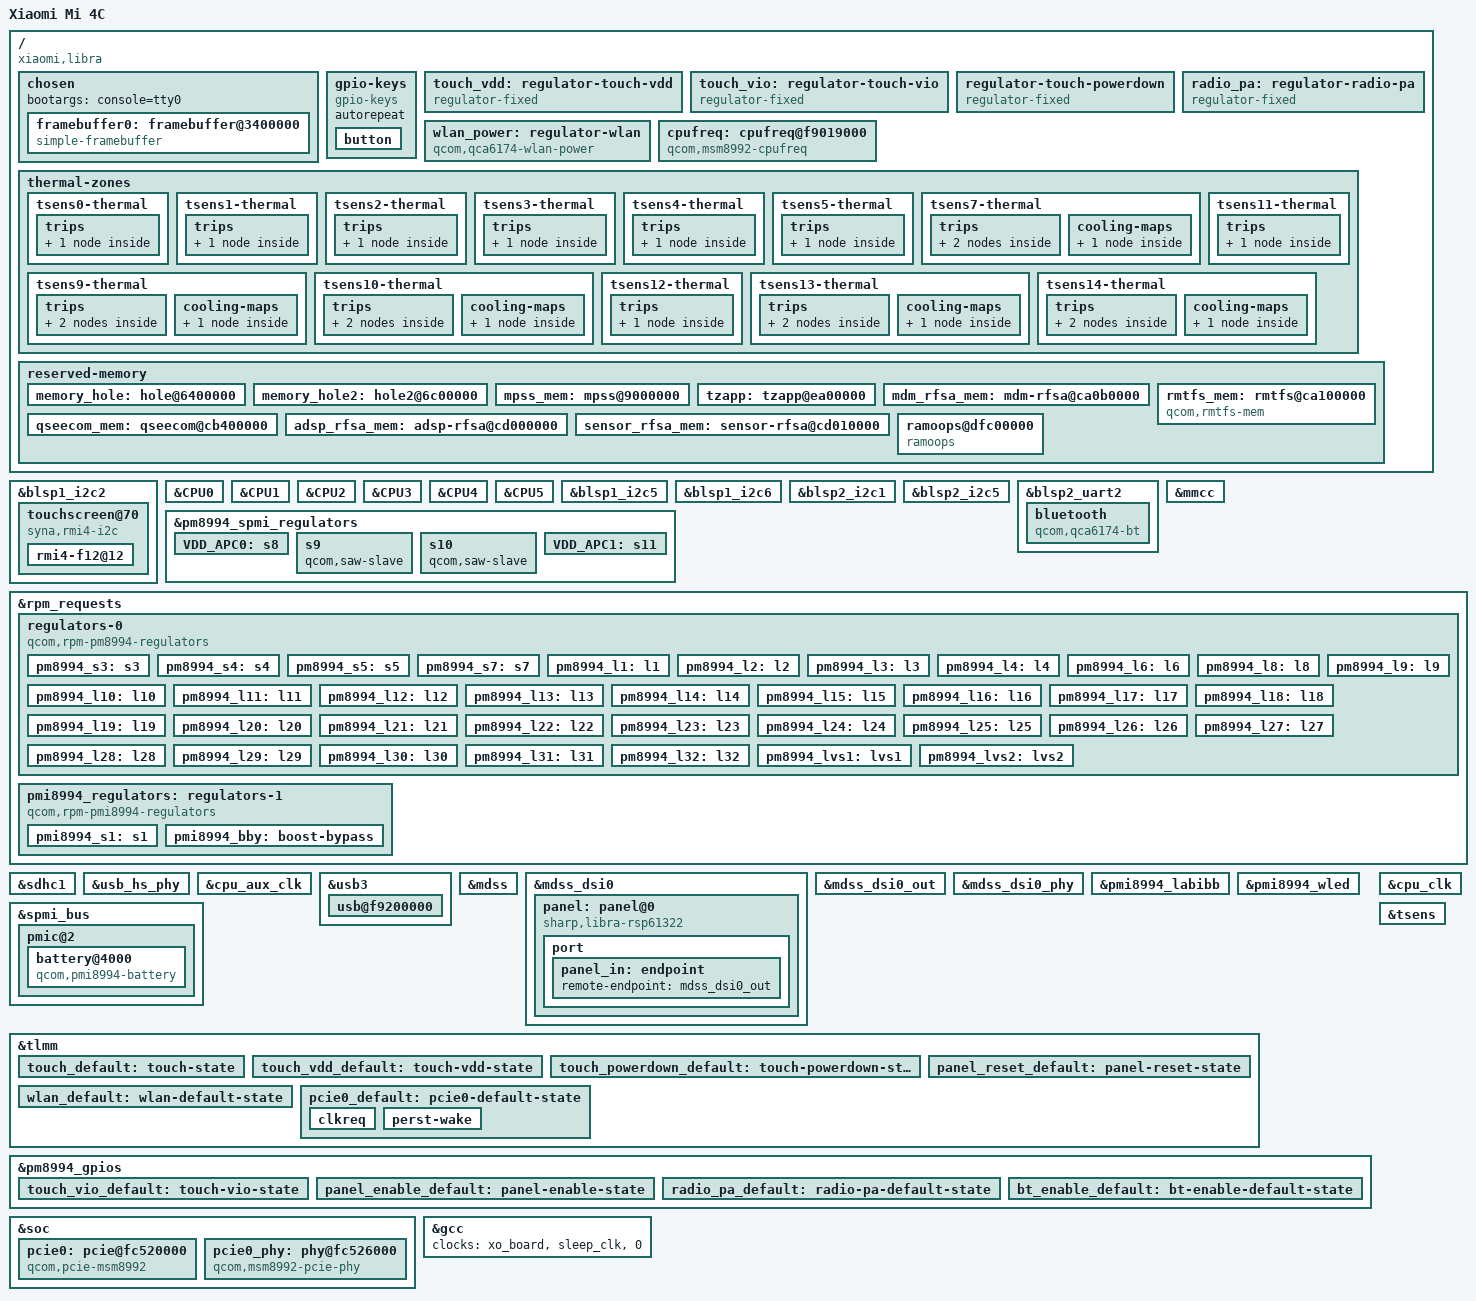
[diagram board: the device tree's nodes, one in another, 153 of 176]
// SPDX-License-Identifier: BSD-3-Clause
/*
 * Copyright (c) 2020, Konrad Dybcio
 */

/dts-v1/;

#include "msm8992.dtsi"
#include "pm8994.dtsi"
#include "pmi8994.dtsi"
#include <dt-bindings/gpio/gpio.h>
#include <dt-bindings/input/gpio-keys.h>
#include <dt-bindings/thermal/thermal.h>

/delete-node/ &adsp_mem;
/delete-node/ &audio_mem;
/delete-node/ &mpss_mem;
/delete-node/ &peripheral_region;
/delete-node/ &res_hyp_mem;
/delete-node/ &rmtfs_mem;

/ {
	model = "Xiaomi Mi 4C";
	compatible = "xiaomi,libra", "qcom,msm8992";
	chassis-type = "handset";

	/* required for bootloader to select correct board */
	qcom,msm-id = <251 0>, <252 0>;
	qcom,pmic-id = <65545 65546 0 0>;
	qcom,board-id = <12 0>;

	chosen {
		bootargs = "console=tty0";

		#address-cells = <2>;
		#size-cells = <2>;
		ranges;

		framebuffer0: framebuffer@3400000 {
			status = "okay";
			compatible = "simple-framebuffer";
			reg = <0 0x3400000 0 (1080 * 1920 * 3)>;
			width = <1080>;
			height = <1920>;
			stride = <(1080 * 3)>;
			format = "r8g8b8";
			/*
			 * Hold firmware display resources until native DRM handover.
			 */
			clocks = <&mmcc MDSS_AHB_CLK>,
				 <&mmcc MDSS_AXI_CLK>,
				 <&mmcc MDSS_VSYNC_CLK>,
				 <&mmcc MDSS_MDP_CLK>,
				 <&mmcc MDSS_BYTE0_CLK>,
				 <&mmcc MDSS_PCLK0_CLK>,
				 <&mmcc MDSS_ESC0_CLK>;
			power-domains = <&mmcc MDSS_GDSC>;
		};
	};

	gpio-keys {
		compatible = "gpio-keys";
		autorepeat;

		button {
			label = "Volume Up";
			gpios = <&pm8994_gpios 3 GPIO_ACTIVE_LOW>;
			linux,input-type = <1>;
			linux,code = <KEY_VOLUMEUP>;
			wakeup-source;
			debounce-interval = <15>;
		};
	};

	/* External touch rails and power-down control from factory x11 DTS. */
	touch_vdd: regulator-touch-vdd {
		compatible = "regulator-fixed";
		regulator-name = "ts_vreg";
		regulator-min-microvolt = <3100000>;
		regulator-max-microvolt = <3100000>;
		gpio = <&tlmm 110 GPIO_ACTIVE_HIGH>;
		enable-active-high;
		startup-delay-us = <10000>;
		pinctrl-names = "default";
		pinctrl-0 = <&touch_vdd_default>;
	};

	touch_vio: regulator-touch-vio {
		compatible = "regulator-fixed";
		regulator-name = "tp1v8_vreg";
		regulator-min-microvolt = <1800000>;
		regulator-max-microvolt = <1800000>;
		gpio = <&pm8994_gpios 2 GPIO_ACTIVE_HIGH>;
		enable-active-high;
		startup-delay-us = <10000>;
		pinctrl-names = "default";
		pinctrl-0 = <&touch_vio_default>;
	};

	regulator-touch-powerdown {
		compatible = "regulator-fixed";
		regulator-name = "tpwdn_vreg";
		regulator-min-microvolt = <3100000>;
		regulator-max-microvolt = <3100000>;
		gpio = <&tlmm 96 GPIO_ACTIVE_HIGH>;
		enable-active-high;
		startup-delay-us = <5000>;
		regulator-always-on;
		pinctrl-names = "default";
		pinctrl-0 = <&touch_powerdown_default>;
	};

	/* One shared OEM PA switch, refcounted by WLAN and Bluetooth. */
	radio_pa: regulator-radio-pa {
		compatible = "regulator-fixed";
		regulator-name = "qca6174-pa";
		gpio = <&pm8994_gpios 9 GPIO_ACTIVE_HIGH>;
		enable-active-high;
		startup-delay-us = <4000>;
		pinctrl-names = "default";
		pinctrl-0 = <&radio_pa_default>;
	};

	wlan_power: regulator-wlan {
		compatible = "qcom,qca6174-wlan-power";
		regulator-name = "qca6174-wlan";
		vddpa-supply = <&radio_pa>;
		vddio-supply = <&pm8994_s4>;
		vddxo-supply = <&pm8994_l30>;
		enable-gpios = <&tlmm 113 GPIO_ACTIVE_HIGH>;
		bootstrap-gpios = <&tlmm 112 GPIO_ACTIVE_HIGH>,
				  <&tlmm 54 GPIO_ACTIVE_HIGH>,
				  <&tlmm 53 GPIO_ACTIVE_HIGH>;
		pinctrl-names = "default";
		pinctrl-0 = <&wlan_default>;
	};

	cpufreq: cpufreq@f9019000 {
		compatible = "qcom,msm8992-cpufreq";
		reg = <0 0xf9019000 0 0x1000>, <0 0xf901a000 0 0x1000>;
		clocks = <&cpu_clk 0>, <&cpu_clk 1>, <&cpu_clk 2>;
		clock-names = "a53", "a57", "cci";
		apc0-supply = <&VDD_APC0>;
		apc1-supply = <&VDD_APC1>;
		qcom,saw-regs = <&apc0_saw>, <&apc1_saw>;
		power-domains = <&rpmpd MSM8994_VDDMX_AO>;
		nvmem-cells = <&cpr_row62>, <&cpr_row137>, <&cpr_row22>, <&cpr_row138>, <&cpr_row139>, <&cpr_row140>, <&cpr_row56>, <&cpr_row57>, <&cpr_row136>, <&cpu_speedbin>;
		nvmem-cell-names = "cpr-row62", "cpr-row137", "cpr-row22", "cpr-row138", "cpr-row139", "cpr-row140", "cpr-row56", "cpr-row57", "cpr-row136", "speedbin";
	};

	/* Factory polling, mitigation and emergency temperature limits. */
	thermal-zones {
		tsens0-thermal {
			polling-delay-passive = <250>;
			polling-delay = <250>;
			thermal-sensors = <&tsens 0>;
			trips {
				critical {
					temperature = <115000>;
					hysteresis = <0>;
					type = "critical";
				};
			};
		};
		tsens1-thermal {
			polling-delay-passive = <250>;
			polling-delay = <250>;
			thermal-sensors = <&tsens 1>;
			trips {
				critical {
					temperature = <115000>;
					hysteresis = <0>;
					type = "critical";
				};
			};
		};
		tsens2-thermal {
			polling-delay-passive = <250>;
			polling-delay = <250>;
			thermal-sensors = <&tsens 2>;
			trips {
				critical {
					temperature = <115000>;
					hysteresis = <0>;
					type = "critical";
				};
			};
		};
		tsens3-thermal {
			polling-delay-passive = <250>;
			polling-delay = <250>;
			thermal-sensors = <&tsens 3>;
			trips {
				critical {
					temperature = <115000>;
					hysteresis = <0>;
					type = "critical";
				};
			};
		};
		tsens4-thermal {
			polling-delay-passive = <250>;
			polling-delay = <250>;
			thermal-sensors = <&tsens 4>;
			trips {
				critical {
					temperature = <115000>;
					hysteresis = <0>;
					type = "critical";
				};
			};
		};
		tsens5-thermal {
			polling-delay-passive = <250>;
			polling-delay = <250>;
			thermal-sensors = <&tsens 5>;
			trips {
				critical {
					temperature = <115000>;
					hysteresis = <0>;
					type = "critical";
				};
			};
		};
		tsens7-thermal {
			polling-delay-passive = <250>;
			polling-delay = <250>;
			thermal-sensors = <&tsens 7>;
			trips {
				tsens7_passive: passive {
					temperature = <60000>;
					hysteresis = <10000>;
					type = "passive";
				};
				critical {
					temperature = <115000>;
					hysteresis = <0>;
					type = "critical";
				};
			};
			cooling-maps {
				map {
					trip = <&tsens7_passive>;
					cooling-device = <&CPU0 THERMAL_NO_LIMIT THERMAL_NO_LIMIT>, <&CPU4 THERMAL_NO_LIMIT THERMAL_NO_LIMIT>;
				};
			};
		};
		tsens9-thermal {
			polling-delay-passive = <250>;
			polling-delay = <250>;
			thermal-sensors = <&tsens 9>;
			trips {
				tsens9_passive: passive {
					temperature = <60000>;
					hysteresis = <10000>;
					type = "passive";
				};
				critical {
					temperature = <115000>;
					hysteresis = <0>;
					type = "critical";
				};
			};
			cooling-maps {
				map {
					trip = <&tsens9_passive>;
					cooling-device = <&CPU0 THERMAL_NO_LIMIT THERMAL_NO_LIMIT>;
				};
			};
		};
		tsens10-thermal {
			polling-delay-passive = <250>;
			polling-delay = <250>;
			thermal-sensors = <&tsens 10>;
			trips {
				tsens10_passive: passive {
					temperature = <60000>;
					hysteresis = <10000>;
					type = "passive";
				};
				critical {
					temperature = <115000>;
					hysteresis = <0>;
					type = "critical";
				};
			};
			cooling-maps {
				map {
					trip = <&tsens10_passive>;
					cooling-device = <&CPU0 THERMAL_NO_LIMIT THERMAL_NO_LIMIT>;
				};
			};
		};
		tsens11-thermal {
			polling-delay-passive = <250>;
			polling-delay = <250>;
			thermal-sensors = <&tsens 11>;
			trips {
				critical {
					temperature = <115000>;
					hysteresis = <0>;
					type = "critical";
				};
			};
		};
		tsens12-thermal {
			polling-delay-passive = <250>;
			polling-delay = <250>;
			thermal-sensors = <&tsens 12>;
			trips {
				critical {
					temperature = <115000>;
					hysteresis = <0>;
					type = "critical";
				};
			};
		};
		tsens13-thermal {
			polling-delay-passive = <250>;
			polling-delay = <250>;
			thermal-sensors = <&tsens 13>;
			trips {
				tsens13_passive: passive {
					temperature = <60000>;
					hysteresis = <10000>;
					type = "passive";
				};
				critical {
					temperature = <115000>;
					hysteresis = <0>;
					type = "critical";
				};
			};
			cooling-maps {
				map {
					trip = <&tsens13_passive>;
					cooling-device = <&CPU4 THERMAL_NO_LIMIT THERMAL_NO_LIMIT>;
				};
			};
		};
		tsens14-thermal {
			polling-delay-passive = <250>;
			polling-delay = <250>;
			thermal-sensors = <&tsens 14>;
			trips {
				tsens14_passive: passive {
					temperature = <60000>;
					hysteresis = <10000>;
					type = "passive";
				};
				critical {
					temperature = <115000>;
					hysteresis = <0>;
					type = "critical";
				};
			};
			cooling-maps {
				map {
					trip = <&tsens14_passive>;
					cooling-device = <&CPU4 THERMAL_NO_LIMIT THERMAL_NO_LIMIT>;
				};
			};
		};
	};

	reserved-memory {
		#address-cells = <2>;
		#size-cells = <2>;
		ranges;

		memory_hole: hole@6400000 {
			reg = <0 0x06400000 0 0x600000>;
			no-map;
		};

		memory_hole2: hole2@6c00000 {
			reg = <0 0x06c00000 0 0x2400000>;
			no-map;
		};

		mpss_mem: mpss@9000000 {
			reg = <0 0x09000000 0 0x5a00000>;
			no-map;
		};

		tzapp: tzapp@ea00000 {
			reg = <0 0x0ea00000 0 0x1900000>;
			no-map;
		};

		mdm_rfsa_mem: mdm-rfsa@ca0b0000 {
			reg = <0 0xca0b0000 0 0x10000>;
			no-map;
		};

		rmtfs_mem: rmtfs@ca100000 {
			compatible = "qcom,rmtfs-mem";
			reg = <0 0xca100000 0 0x180000>;
			no-map;

			qcom,client-id = <1>;
		};

		qseecom_mem: qseecom@cb400000 {
			reg = <0 0xcb400000 0 0x1c00000>;
			no-mem;
		};

		adsp_rfsa_mem: adsp-rfsa@cd000000 {
			reg = <0 0xcd000000 0 0x10000>;
			no-map;
		};

		sensor_rfsa_mem: sensor-rfsa@cd010000 {
			reg = <0 0xcd010000 0 0x10000>;
			no-map;
		};

		ramoops@dfc00000 {
			compatible = "ramoops";
			reg = <0 0xdfc00000 0 0x40000>;
			console-size = <0x10000>;
			record-size = <0x10000>;
			pmsg-size = <0x20000>;
		};
	};
};

&blsp1_i2c2 {
	status = "okay";

	/* TWRP confirms Biel/Sharp Synaptics DSX at 0x70 with F01/F12. */
	touchscreen@70 {
		compatible = "syna,rmi4-i2c";
		reg = <0x70>;
		interrupt-parent = <&tlmm>;
		interrupts = <61 IRQ_TYPE_LEVEL_LOW>;
		reset-gpios = <&tlmm 60 GPIO_ACTIVE_LOW>;
		vdd-supply = <&touch_vdd>;
		vio-supply = <&touch_vio>;
		pinctrl-names = "default";
		pinctrl-0 = <&touch_default>;
		syna,startup-delay-ms = <5>;
		syna,reset-delay-ms = <15>;
		#address-cells = <1>;
		#size-cells = <0>;

		rmi4-f12@12 {
			reg = <0x12>;
			syna,sensor-type = <1>;
		};
	};
};

&CPU0 {
	clocks = <&cpu_clk 0>;
	#cooling-cells = <2>;
	enable-method = "qcom,8994-arm-cortex-acc";
	qcom,acc = <&acc0>;
	qcom,l2-power = <&cpu_power>;
	qcom,ldo-retention-voltage = <0x2a>;
};

&CPU1 {
	clocks = <&cpu_clk 0>;
	#cooling-cells = <2>;
	enable-method = "qcom,8994-arm-cortex-acc";
	qcom,acc = <&acc1>;
	qcom,l2-power = <&cpu_power>;
	qcom,ldo-retention-voltage = <0x2a>;
};

&CPU2 {
	clocks = <&cpu_clk 0>;
	#cooling-cells = <2>;
	enable-method = "qcom,8994-arm-cortex-acc";
	qcom,acc = <&acc2>;
	qcom,l2-power = <&cpu_power>;
	qcom,ldo-retention-voltage = <0x2a>;
};

&CPU3 {
	clocks = <&cpu_clk 0>;
	#cooling-cells = <2>;
	enable-method = "qcom,8994-arm-cortex-acc";
	qcom,acc = <&acc3>;
	qcom,l2-power = <&cpu_power>;
	qcom,ldo-retention-voltage = <0x2a>;
};

&CPU4 {
	clocks = <&cpu_clk 1>;
	#cooling-cells = <2>;
	enable-method = "qcom,8994-arm-cortex-acc";
	qcom,acc = <&acc4>;
	qcom,l2-power = <&cpu_power>;
	qcom,ldo-retention-voltage = <0x3e>;
};

&CPU5 {
	clocks = <&cpu_clk 1>;
	#cooling-cells = <2>;
	enable-method = "qcom,8994-arm-cortex-acc";
	qcom,acc = <&acc5>;
	qcom,l2-power = <&cpu_power>;
	qcom,ldo-retention-voltage = <0x3e>;
};

&blsp1_i2c5 {
	status = "okay";

	/* ST lsm6db0 gyro/accelerometer */
};

&blsp1_i2c6 {
	status = "okay";

	/*
	 * NXP NCI NFC,
	 * TI USB320 Type-C controller,
	 * Pericom 30216a USB (de)mux switch
	 */
};

&blsp2_i2c1 {
	status = "okay";

	/* cm36686 proximity and ambient light sensor */
};

&blsp2_i2c5 {
	status = "okay";

	/* Silabs si4705 FM transmitter */
};

&blsp2_uart2 {
	status = "okay";

	bluetooth {
		compatible = "qcom,qca6174-bt";
		enable-gpios = <&pm8994_gpios 19 GPIO_ACTIVE_HIGH>;
		vddio-supply = <&pm8994_s4>;
		vddxo-supply = <&pm8994_l30>;
		vddrf-supply = <&radio_pa>;
		pinctrl-names = "default";
		pinctrl-0 = <&bt_enable_default>;
		max-speed = <3000000>;
		firmware-name = "btnv32.bin";
	};
};

&mmcc {
	/* Resolve DSI clocks by name when the MSM module registers its PLL.
	 * Direct PHY phandles would defer MMCC, which also supplies PHY AHB.
	 */
	clocks = <&xo_board>,
		 <&gcc GPLL0_OUT_MMSSCC>,
		 <&rpmcc RPM_SMD_MMSSNOC_AHB_CLK>,
		 <&rpmcc RPM_SMD_GFX3D_CLK_SRC>,
		 <0>, <0>, <0>, <0>, <0>;
};

&pm8994_spmi_regulators {
	VDD_APC0: s8 {
		qcom,saw-reg = <&apc0_saw>;
		qcom,saw-leader;
		qcom,saw-cpu = <&CPU0>;
		regulator-min-microvolt = <680000>;
		regulator-max-microvolt = <1180000>;
		regulator-always-on;
		regulator-boot-on;
	};

	/* APC1 is 3-phase, but quoting downstream, s11 is "the gang leader" */
	s9 {
		qcom,saw-slave;
	};

	s10 {
		qcom,saw-slave;
	};

	VDD_APC1: s11 {
		qcom,saw-reg = <&apc1_saw>;
		qcom,saw-leader;
		qcom,saw-cpu = <&CPU4>;
		regulator-min-microvolt = <700000>;
		regulator-max-microvolt = <1225000>;
		regulator-always-on;
		regulator-boot-on;
	};
};

&rpm_requests {
	regulators-0 {
		compatible = "qcom,rpm-pm8994-regulators";

		vdd_l1-supply = <&pm8994_s7>;
		vdd_l2_26_28-supply = <&pm8994_s3>;
		vdd_l3_11-supply = <&pm8994_s3>;
		vdd_l4_27_31-supply = <&pm8994_s3>;
		vdd_l5_7-supply = <&pm8994_s3>;
		vdd_l6_12_32-supply = <&pm8994_s5>;
		vdd_l8_16_30-supply = <&vph_pwr>;
		vdd_l9_10_18_22-supply = <&vph_pwr>;
		vdd_l13_19_23_24-supply = <&vph_pwr>;
		vdd_l14_15-supply = <&pm8994_s5>;
		vdd_l17_29-supply = <&vph_pwr>;
		vdd_l20_21-supply = <&vph_pwr>;
		vdd_l25-supply = <&pm8994_s5>;
		vdd_lvs1_2-supply = <&pm8994_s4>;

		/* S1, S2, S6 and S12 are managed by RPMPD */

		pm8994_s3: s3 {
			regulator-min-microvolt = <1300000>;
			regulator-max-microvolt = <1300000>;
		};

		pm8994_s4: s4 {
			regulator-min-microvolt = <1800000>;
			regulator-max-microvolt = <1800000>;
			regulator-allow-set-load;
			regulator-always-on;
			regulator-system-load = <325000>;
		};

		pm8994_s5: s5 {
			regulator-min-microvolt = <2150000>;
			regulator-max-microvolt = <2150000>;
		};

		pm8994_s7: s7 {
			regulator-min-microvolt = <1000000>;
			regulator-max-microvolt = <1000000>;
		};

		/* S8, S9, S10 and S11 - SPMI-managed VDD_APC */

		pm8994_l1: l1 {
			regulator-min-microvolt = <1000000>;
			regulator-max-microvolt = <1000000>;
		};

		pm8994_l2: l2 {
			regulator-min-microvolt = <1250000>;
			regulator-max-microvolt = <1250000>;
		};

		pm8994_l3: l3 {
			regulator-min-microvolt = <1200000>;
			regulator-max-microvolt = <1200000>;
		};

		pm8994_l4: l4 {
			regulator-min-microvolt = <1225000>;
			regulator-max-microvolt = <1225000>;
		};

		/* L5 is inaccessible from RPM */

		pm8994_l6: l6 {
			regulator-min-microvolt = <1800000>;
			regulator-max-microvolt = <1800000>;
		};

		/* L7 is inaccessible from RPM */

		pm8994_l8: l8 {
			regulator-min-microvolt = <1800000>;
			regulator-max-microvolt = <1800000>;
		};

		pm8994_l9: l9 {
			regulator-min-microvolt = <1800000>;
			regulator-max-microvolt = <1800000>;
		};

		pm8994_l10: l10 {
			regulator-min-microvolt = <1800000>;
			regulator-max-microvolt = <1800000>;
		};

		pm8994_l11: l11 {
			regulator-min-microvolt = <1200000>;
			regulator-max-microvolt = <1200000>;
		};

		pm8994_l12: l12 {
			regulator-min-microvolt = <1800000>;
			regulator-max-microvolt = <1800000>;
		};

		pm8994_l13: l13 {
			regulator-min-microvolt = <1800000>;
			regulator-max-microvolt = <2950000>;
		};

		pm8994_l14: l14 {
			regulator-min-microvolt = <1800000>;
			regulator-max-microvolt = <1800000>;
		};

		pm8994_l15: l15 {
			regulator-min-microvolt = <1800000>;
			regulator-max-microvolt = <1800000>;
		};

		pm8994_l16: l16 {
			regulator-min-microvolt = <2700000>;
			regulator-max-microvolt = <2700000>;
		};

		pm8994_l17: l17 {
			regulator-min-microvolt = <2700000>;
			regulator-max-microvolt = <2700000>;
		};

		pm8994_l18: l18 {
			regulator-min-microvolt = <2850000>;
			regulator-max-microvolt = <2850000>;
			regulator-always-on;
		};

		pm8994_l19: l19 {
			regulator-min-microvolt = <2800000>;
			regulator-max-microvolt = <2800000>;
		};

		pm8994_l20: l20 {
			regulator-min-microvolt = <2950000>;
			regulator-max-microvolt = <2950000>;
			regulator-always-on;
			regulator-boot-on;
			regulator-allow-set-load;
			regulator-system-load = <570000>;
		};

		pm8994_l21: l21 {
			regulator-min-microvolt = <2950000>;
			regulator-max-microvolt = <2950000>;
			regulator-always-on;
		};

		pm8994_l22: l22 {
			regulator-min-microvolt = <3000000>;
			regulator-max-microvolt = <3000000>;
		};

		pm8994_l23: l23 {
			regulator-min-microvolt = <2800000>;
			regulator-max-microvolt = <2800000>;
		};

		pm8994_l24: l24 {
			regulator-min-microvolt = <3075000>;
			regulator-max-microvolt = <3150000>;
		};

		pm8994_l25: l25 {
			regulator-min-microvolt = <1000000>;
			regulator-max-microvolt = <1000000>;
		};

		pm8994_l26: l26 {
			regulator-min-microvolt = <987500>;
			regulator-max-microvolt = <987500>;

		};

		pm8994_l27: l27 {
			regulator-min-microvolt = <1050000>;
			regulator-max-microvolt = <1050000>;
		};

		pm8994_l28: l28 {
			regulator-min-microvolt = <1000000>;
			regulator-max-microvolt = <1000000>;
		};

		pm8994_l29: l29 {
			regulator-min-microvolt = <2800000>;
			regulator-max-microvolt = <2800000>;
		};

		pm8994_l30: l30 {
			regulator-min-microvolt = <1800000>;
			regulator-max-microvolt = <1800000>;
		};

		pm8994_l31: l31 {
			regulator-min-microvolt = <1262500>;
			regulator-max-microvolt = <1262500>;
		};

		pm8994_l32: l32 {
			regulator-min-microvolt = <1800000>;
			regulator-max-microvolt = <1800000>;
		};

		pm8994_lvs1: lvs1 {};
		pm8994_lvs2: lvs2 {};
	};

	pmi8994_regulators: regulators-1 {
		compatible = "qcom,rpm-pmi8994-regulators";
		vdd_s1-supply = <&vph_pwr>;
		vdd_bst_byp-supply = <&vph_pwr>;

		pmi8994_s1: s1 {
			regulator-min-microvolt = <1025000>;
			regulator-max-microvolt = <1025000>;
		};

		/* S2 & S3 - VDD_GFX */

		pmi8994_bby: boost-bypass {
			regulator-min-microvolt = <3150000>;
			regulator-max-microvolt = <3600000>;
		};
	};
};

&sdhc1 {
	status = "okay";

	mmc-hs400-1_8v;
	vmmc-supply = <&pm8994_l20>;
	vqmmc-supply = <&pm8994_s4>;
};

&usb_hs_phy {
	vdda1p8-supply = <&pm8994_l6>;
	vdda3p3-supply = <&pm8994_l24>;
	status = "okay";
};

&cpu_aux_clk {
	status = "okay";
};

&usb3 {
	usb@f9200000 {
		phys = <&usb_hs_phy>;
		phy-names = "usb2-phy";
		snps,hsphy_interface = "utmi";
	};
};

&mdss {
	status = "okay";
};

&mdss_dsi0 {
	status = "okay";
	vdda-supply = <&pm8994_l2>;
	vddio-supply = <&pm8994_l12>;
	vcca-supply = <&pm8994_l28>;
	vdd-supply = <&pm8994_l14>;

	panel: panel@0 {
		compatible = "sharp,libra-rsp61322";
		reg = <0>;
		avdd-supply = <&pmi8994_lab>;
		avee-supply = <&pmi8994_ibb>;
		reset-gpios = <&tlmm 78 GPIO_ACTIVE_LOW>;
		enable-gpios = <&pm8994_gpios 14 GPIO_ACTIVE_HIGH>;
		backlight = <&pmi8994_wled>;
		pinctrl-names = "default";
		pinctrl-0 = <&panel_reset_default &panel_enable_default>;
		port {
			panel_in: endpoint {
				remote-endpoint = <&mdss_dsi0_out>;
			};
		};
	};
};

&mdss_dsi0_out {
	remote-endpoint = <&panel_in>;
	data-lanes = <0 1 2 3>;
};

&mdss_dsi0_phy {
	status = "okay";
	vddio-supply = <&pm8994_l12>;
	vcca-supply = <&pm8994_l28>;
};

&pmi8994_labibb {
	status = "okay";
};

&pmi8994_wled {
	status = "okay";
	/* Linux controls brightness directly without a panel CABC PWM signal. */
	/delete-property/ qcom,cabc;
	/* Illuminate only after native fbcon scanout has been checked. */
	default-brightness = <0>;
	qcom,fdbk-output = "auto";
	qcom,vref-mv = <350>;
	/* The selected factory DT overrides the vendor's generic 104 ns default. */
	qcom,boost-duty-ns = <26>;
	qcom,mod-freq-khz = <9600>;
	qcom,dim-mode = "hybrid";
	qcom,hyb-thres = <625>;
	qcom,sync-dly-us = <800>;
	qcom,en-phase-stag;
	qcom,current-limit-microamp = <20000>;
	/* Vendor ILIM encoding: 980 / 280 = 3; WLED4 table entry 3 is 620. */
	qcom,current-boost-limit = <620>;
	qcom,switching-freq = <600>;
	qcom,ovp-millivolt = <29500>;
	qcom,enabled-strings = <0 1>;
};

&spmi_bus {
	pmic@2 {
		battery@4000 {
			compatible = "qcom,pmi8994-battery";
			reg = <0x4000>;
			/* OEM x11 fastchg-current-ma=1800, float-voltage-mv=4400. */
			qcom,fast-charge-current-max-microamp = <1800000>;
			qcom,battery-voltage-max-microvolt = <4400000>;
			interrupts = <2 0x40 4 IRQ_TYPE_EDGE_BOTH>,
				     <2 0x40 1 IRQ_TYPE_EDGE_BOTH>,
				     <2 0x41 6 IRQ_TYPE_EDGE_BOTH>,
				     <2 0x13 2 IRQ_TYPE_EDGE_BOTH>,
				     <2 0x12 0 IRQ_TYPE_EDGE_BOTH>,
				     <2 0x12 2 IRQ_TYPE_EDGE_BOTH>;
			interrupt-names = "delta-soc", "low-soc", "batt-missing",
					  "usb-source", "batt-hot", "batt-cold";
		};
	};
};

&tlmm {
	touch_default: touch-state {
		pins = "gpio60", "gpio61";
		function = "gpio";
		drive-strength = <16>;
		bias-pull-up;
	};

	touch_vdd_default: touch-vdd-state {
		pins = "gpio110";
		function = "gpio";
		drive-strength = <16>;
		bias-pull-up;
	};

	touch_powerdown_default: touch-powerdown-state {
		pins = "gpio96";
		function = "gpio";
		drive-strength = <16>;
		bias-pull-up;
	};

	panel_reset_default: panel-reset-state {
		pins = "gpio78";
		function = "gpio";
		drive-strength = <8>;
		bias-disable;
	};
};

&pm8994_gpios {
	touch_vio_default: touch-vio-state {
		pins = "gpio2";
		function = "normal";
		power-source = <2>;
		bias-disable;
	};

	panel_enable_default: panel-enable-state {
		pins = "gpio14";
		function = "normal";
		power-source = <2>;
		bias-disable;
	};
};

&cpu_clk {
	status = "okay";
};

&tsens {
	status = "okay";
};

/* OEM PCIe0 aperture and 20nm PHY, separate from the working USB PHY. */
&soc {
	pcie0: pcie@fc520000 {
		compatible = "qcom,pcie-msm8992";
		device_type = "pci";
		reg = <0xfc520000 0x2000>, <0xff000000 0xf1d>,
		      <0xff000f20 0xa8>, <0xff100000 0x100000>;
		reg-names = "parf", "dbi", "elbi", "config";
		#address-cells = <3>;
		#size-cells = <2>;
		#interrupt-cells = <1>;
		bus-range = <0 0xff>;
		linux,pci-domain = <0>;
		num-lanes = <1>;
		ranges = <0x01000000 0 0xff200000 0xff200000 0 0x100000>,
			 <0x02000000 0 0xff300000 0xff300000 0 0xd00000>;
		interrupts = <GIC_SPI 243 IRQ_TYPE_LEVEL_HIGH>;
		interrupt-names = "msi";
		interrupt-map-mask = <0 0 0 7>;
		interrupt-map = <0 0 0 1 &intc 0 244 IRQ_TYPE_LEVEL_HIGH>,
				<0 0 0 2 &intc 0 245 IRQ_TYPE_LEVEL_HIGH>,
				<0 0 0 3 &intc 0 247 IRQ_TYPE_LEVEL_HIGH>,
				<0 0 0 4 &intc 0 248 IRQ_TYPE_LEVEL_HIGH>;
		clocks = <&rpmcc RPM_SMD_LN_BB_CLK>,
			 <&gcc GCC_PCIE_0_AUX_CLK>,
			 <&gcc GCC_PCIE_0_CFG_AHB_CLK>,
			 <&gcc GCC_PCIE_0_MSTR_AXI_CLK>,
			 <&gcc GCC_PCIE_0_SLV_AXI_CLK>,
			 <&gcc PCIE_0_PHY_LDO>;
		clock-names = "ref", "aux", "cfg", "bus_master", "bus_slave", "ldo";
		power-domains = <&gcc PCIE_0_GDSC>;
		resets = <&gcc PCIE_PHY_0_RESET>;
		reset-names = "phy";

		vdda-supply = <&pm8994_l12>;
		vdda_phy-supply = <&pm8994_l28>;
		vddpe-3v3-supply = <&wlan_power>;
		perst-gpios = <&tlmm 35 GPIO_ACTIVE_LOW>;
		wake-gpios = <&tlmm 37 GPIO_ACTIVE_LOW>;
		pinctrl-names = "default";
		pinctrl-0 = <&pcie0_default>;
		phys = <&pcie0_phy>;
		phy-names = "pciephy";
	};

	pcie0_phy: phy@fc526000 {
		compatible = "qcom,msm8992-pcie-phy";
		reg = <0xfc526000 0x1000>;
		clocks = <&gcc GCC_PCIE_0_PIPE_CLK>;
		clock-names = "pipe";
		resets = <&gcc PCIE_PHY_0_PIPE_RESET>;
		reset-names = "pipe";
		#phy-cells = <0>;
		#clock-cells = <0>;
	};
};

&gcc {
	/* Resolve the PHY's PIPE output by name to avoid a GCC/PHY probe cycle. */
	clocks = <&xo_board>, <&sleep_clk>, <0>;
	clock-names = "xo", "sleep", "pcie0_pipe";
};

&tlmm {
	wlan_default: wlan-default-state {
		pins = "gpio112", "gpio54", "gpio53", "gpio113";
		function = "gpio";
		drive-strength = <16>;
		bias-pull-down;
	};

	pcie0_default: pcie0-default-state {
		clkreq {
			pins = "gpio36";
			/* GPIO36 function 2, named pci_e1 in the MSM8994 mux table. */
			function = "pci_e1";
			drive-strength = <2>;
			bias-pull-up;
		};
		perst-wake {
			pins = "gpio35", "gpio37";
			function = "gpio";
			drive-strength = <2>;
			bias-pull-down;
		};
	};
};

&pm8994_gpios {
	radio_pa_default: radio-pa-default-state {
		pins = "gpio9";
		function = "normal";
		power-source = <0>;
		qcom,drive-strength = <1>;
		bias-disable;
	};

	bt_enable_default: bt-enable-default-state {
		pins = "gpio19";
		function = "normal";
		power-source = <2>;
		bias-pull-down;
	};
};
